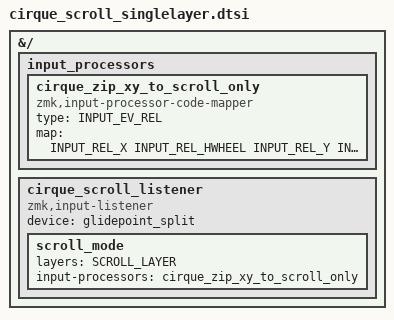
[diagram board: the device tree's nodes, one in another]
/* config/cirque_scroll_singlelayer.dtsi
 *
 * Hold-to-scroll on Cirque with ONE layer:
 * - Normal: cursor moves.
 * - Hold scroll key (activates layer): X => horizontal scroll, Y => vertical scroll.
 *
 * Edit SCROLL_LAYER and the Cirque node label as needed.
 */

#include <input/processors.dtsi>
#include <zephyr/dt-bindings/input/input-event-codes.h>

#define SCROLL_LAYER 1   /* single “scroll mode” layer index */

/* Map BOTH axes to scroll while the layer is active (cursor motion suppressed). */
&{/} {
    input_processors {
        cirque_zip_xy_to_scroll_only: cirque_zip_xy_to_scroll_only {
            compatible = "zmk,input-processor-code-mapper";
            #input-processor-cells = <0>;
            type = <INPUT_EV_REL>;
            /* X -> HWHEEL, Y -> WHEEL; map originals to MISC to ignore */
            map = <INPUT_REL_X INPUT_REL_HWHEEL
                   INPUT_REL_Y INPUT_REL_WHEEL
                   INPUT_REL_X INPUT_REL_MISC
                   INPUT_REL_Y INPUT_REL_MISC>;
        };
    };
}

/* Listener for your Cirque device — replace &cirque_tp with your actual node label */
&{/} {
    cirque_scroll_listener: cirque_scroll_listener {
        compatible = "zmk,input-listener";
        device = <&glidepoint_split>; /* <<< change to your Cirque node label */
    };
}

/* Apply the mapper ONLY while the single scroll layer is active */
&cirque_scroll_listener {
    scroll_mode {
        layers = <SCROLL_LAYER>;
        input-processors = <&cirque_zip_xy_to_scroll_only>;
    };
}
